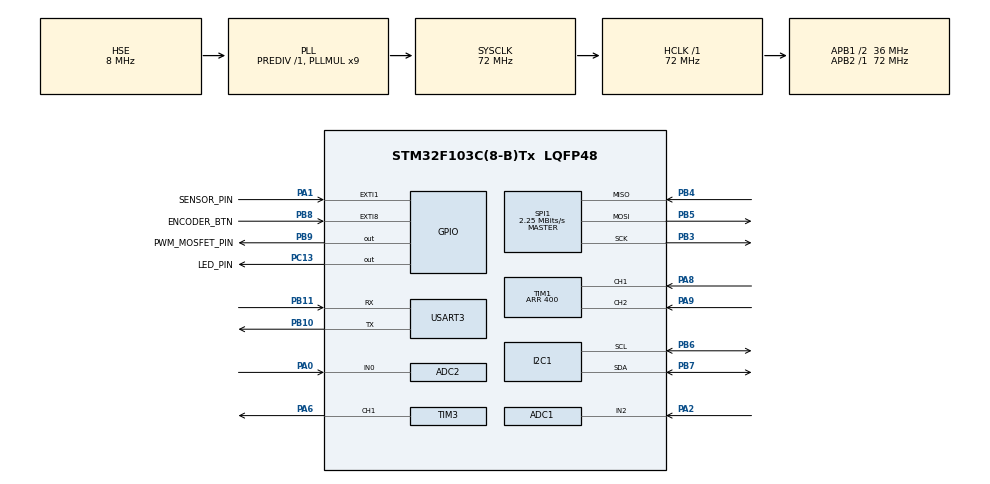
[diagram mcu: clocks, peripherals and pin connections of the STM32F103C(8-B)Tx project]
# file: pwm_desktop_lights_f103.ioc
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ADC1.Channel-1\#ChannelRegularConversion=ADC_CHANNEL_2
ADC1.ContinuousConvMode=ENABLE
ADC1.ExternalTrigConv=ADC_SOFTWARE_START
ADC1.NbrOfConversion=1
ADC1.NbrOfConversionFlag=1
ADC1.Rank-1\#ChannelRegularConversion=1
ADC1.SamplingTime-1\#ChannelRegularConversion=ADC_SAMPLETIME_13CYCLES_5
ADC1.master=1
ADC2.Channel-0\#ChannelRegularConversion=ADC_CHANNEL_0
ADC2.NbrOfConversionFlag=1
ADC2.Rank-0\#ChannelRegularConversion=1
ADC2.SamplingTime-0\#ChannelRegularConversion=ADC_SAMPLETIME_13CYCLES_5
Dma.ADC1.0.Direction=DMA_PERIPH_TO_MEMORY
Dma.ADC1.0.Instance=DMA1_Channel1
Dma.ADC1.0.MemDataAlignment=DMA_MDATAALIGN_HALFWORD
Dma.ADC1.0.MemInc=DMA_MINC_ENABLE
Dma.ADC1.0.Mode=DMA_CIRCULAR
Dma.ADC1.0.PeriphDataAlignment=DMA_PDATAALIGN_HALFWORD
Dma.ADC1.0.PeriphInc=DMA_PINC_DISABLE
Dma.ADC1.0.Priority=DMA_PRIORITY_LOW
Dma.Request0=ADC1
Dma.Request1=USART3_TX
Dma.Request2=USART3_RX
Dma.USART3_RX.2.Direction=DMA_PERIPH_TO_MEMORY
Dma.USART3_RX.2.Instance=DMA1_Channel3
Dma.USART3_RX.2.MemDataAlignment=DMA_MDATAALIGN_BYTE
Dma.USART3_RX.2.MemInc=DMA_MINC_ENABLE
Dma.USART3_RX.2.Mode=DMA_NORMAL
Dma.USART3_RX.2.PeriphDataAlignment=DMA_PDATAALIGN_BYTE
Dma.USART3_RX.2.PeriphInc=DMA_PINC_DISABLE
Dma.USART3_RX.2.Priority=DMA_PRIORITY_LOW
Dma.USART3_TX.1.Direction=DMA_MEMORY_TO_PERIPH
Dma.USART3_TX.1.Instance=DMA1_Channel2
Dma.USART3_TX.1.MemDataAlignment=DMA_MDATAALIGN_BYTE
Dma.USART3_TX.1.MemInc=DMA_MINC_ENABLE
Dma.USART3_TX.1.Mode=DMA_NORMAL
Dma.USART3_TX.1.PeriphDataAlignment=DMA_PDATAALIGN_BYTE
Dma.USART3_TX.1.PeriphInc=DMA_PINC_DISABLE
Dma.USART3_TX.1.Priority=DMA_PRIORITY_LOW
Mcu.Family=STM32F1
Mcu.Name=STM32F103C(8-B)Tx
Mcu.Package=LQFP48
NVIC.ADC1_2_IRQn=true\:0\:0\:false\:false\:true\:true\:true
NVIC.DMA1_Channel1_IRQn=true\:0\:0\:false\:false\:true\:false\:true
NVIC.DMA1_Channel2_IRQn=true\:0\:0\:false\:false\:true\:false\:true
NVIC.DMA1_Channel3_IRQn=true\:0\:0\:false\:false\:true\:false\:true
NVIC.EXTI1_IRQn=true\:0\:0\:false\:false\:true\:true\:true
NVIC.EXTI9_5_IRQn=true\:0\:0\:false\:false\:true\:true\:true
NVIC.I2C1_EV_IRQn=true\:0\:0\:false\:false\:true\:true\:true
NVIC.PriorityGroup=NVIC_PRIORITYGROUP_4
NVIC.SPI1_IRQn=true\:0\:0\:false\:false\:true\:true\:true
NVIC.TIM1_CC_IRQn=true\:0\:0\:false\:false\:true\:true\:true
NVIC.TIM1_TRG_COM_IRQn=true\:0\:0\:false\:false\:true\:true\:true
NVIC.TIM1_UP_IRQn=true\:0\:0\:false\:false\:true\:true\:true
NVIC.TIM2_IRQn=true\:0\:0\:false\:false\:true\:true\:true
NVIC.TIM3_IRQn=true\:0\:0\:false\:false\:true\:true\:true
NVIC.TIM4_IRQn=true\:0\:0\:false\:false\:true\:true\:true
NVIC.USART3_IRQn=true\:0\:0\:false\:false\:true\:true\:true
PA0-WKUP.Signal=ADCx_IN0
PA1.GPIO_Label=SENSOR_PIN
PA1.GPIO_PuPd=GPIO_PULLDOWN
PA1.Signal=GPXTI1
PA13.Mode=Serial_Wire
PA13.Signal=SYS_JTMS-SWDIO
PA14.Mode=Serial_Wire
PA14.Signal=SYS_JTCK-SWCLK
PA2.Signal=ADCx_IN2
PA6.Signal=S_TIM3_CH1
PA8.GPIO_PuPd=GPIO_PULLDOWN
PA8.Signal=S_TIM1_CH1
PA9.GPIO_PuPd=GPIO_PULLDOWN
PA9.Signal=S_TIM1_CH2
PB10.Mode=Asynchronous
PB10.Signal=USART3_TX
PB11.Mode=Asynchronous
PB11.Signal=USART3_RX
PB3.Mode=Full_Duplex_Master
PB3.Signal=SPI1_SCK
PB4.Mode=Full_Duplex_Master
PB4.Signal=SPI1_MISO
PB5.Mode=Full_Duplex_Master
PB5.Signal=SPI1_MOSI
PB6.Mode=I2C
PB6.Signal=I2C1_SCL
PB7.Mode=I2C
PB7.Signal=I2C1_SDA
PB8.GPIO_Label=ENCODER_BTN
PB8.GPIO_ModeDefaultEXTI=GPIO_MODE_IT_RISING_FALLING
PB8.GPIO_PuPd=GPIO_PULLUP
PB8.Signal=GPXTI8
PB9.GPIO_Label=PWM_MOSFET_PIN
PB9.GPIO_PuPd=GPIO_PULLDOWN
PB9.Signal=GPIO_Output
PC13-TAMPER-RTC.GPIO_Label=LED_PIN
PC13-TAMPER-RTC.GPIO_PuPd=GPIO_PULLDOWN
PC13-TAMPER-RTC.Signal=GPIO_Output
PC14-OSC32_IN.Mode=LSE-External-Oscillator
PC14-OSC32_IN.Signal=RCC_OSC32_IN
PC15-OSC32_OUT.Mode=LSE-External-Oscillator
PC15-OSC32_OUT.Signal=RCC_OSC32_OUT
PD0-OSC_IN.Mode=HSE-External-Oscillator
PD0-OSC_IN.Signal=RCC_OSC_IN
PD1-OSC_OUT.Mode=HSE-External-Oscillator
PD1-OSC_OUT.Signal=RCC_OSC_OUT
ProjectManager.HeapSize=0x200
ProjectManager.StackSize=0x400
ProjectManager.TargetToolchain=MDK-ARM V5.27
RCC.ADCPresc=RCC_ADCPCLK2_DIV6
RCC.AHBFreq_Value=72000000
RCC.APB1CLKDivider=RCC_HCLK_DIV2
RCC.APB1Freq_Value=36000000
RCC.APB1TimFreq_Value=72000000
RCC.APB2Freq_Value=72000000
RCC.APB2TimFreq_Value=72000000
RCC.HCLKFreq_Value=72000000
RCC.PLLMUL=RCC_PLL_MUL9
RCC.PLLSourceVirtual=RCC_PLLSOURCE_HSE
RCC.SYSCLKFreq_VALUE=72000000
RCC.SYSCLKSource=RCC_SYSCLKSOURCE_PLLCLK
RCC.USBFreq_Value=72000000
SH.ADCx_IN0.0=ADC2_IN0,IN0
SH.ADCx_IN2.0=ADC1_IN2,IN2
SH.S_TIM1_CH1.0=TIM1_CH1,Encoder_Interface
SH.S_TIM1_CH2.0=TIM1_CH2,Encoder_Interface
SH.S_TIM3_CH1.0=TIM3_CH1,PWM Generation1 CH1
SPI1.BaudRatePrescaler=SPI_BAUDRATEPRESCALER_32
SPI1.CalculateBaudRate=2.25 MBits/s
SPI1.Direction=SPI_DIRECTION_2LINES
SPI1.Mode=SPI_MODE_MASTER
SPI1.VirtualType=VM_MASTER
TIM1.CounterMode=TIM_COUNTERMODE_CENTERALIGNED3
TIM1.EncoderMode=TIM_ENCODERMODE_TI12
TIM1.IC1Filter=2
TIM1.IC2Filter=2
TIM1.Period=400
TIM2.Channel-Output\ Compare2\ No\ Output=TIM_CHANNEL_2
TIM2.OCMode_2=TIM_OCMODE_TOGGLE
TIM2.Period=49
TIM2.Prescaler=72
TIM2.TIM_MasterOutputTrigger=TIM_TRGO_RESET
TIM3.Channel-PWM\ Generation1\ CH1=TIM_CHANNEL_1
TIM3.Period=99
TIM3.Prescaler=72 * 5
TIM4.Channel-Output\ Compare1\ No\ Output=TIM_CHANNEL_1
TIM4.ClockDivision=TIM_CLOCKDIVISION_DIV1
TIM4.OCMode_1=TIM_OCMODE_TOGGLE
TIM4.Period=499
TIM4.Prescaler=7200 * 2
USART3.VirtualMode=VM_ASYNC
VP_TIM2_VS_no_output2.Mode=Output Compare2 No Output
VP_TIM4_VS_no_output1.Mode=Output Compare1 No Output
board=custom

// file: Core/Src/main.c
/* USER CODE BEGIN Header */
/**
  ******************************************************************************
  * @file           : main.c
  * @brief          : Main program body
  ******************************************************************************
  * @attention
  *
  * <h2><center>&copy; Copyright (c) 2019 STMicroelectronics.
  * All rights reserved.</center></h2>
  *
  * This software component is licensed by ST under BSD 3-Clause license,
  * the "License"; You may not use this file except in compliance with the
  * License. You may obtain a copy of the License at:
  *                        opensource.org/licenses/BSD-3-Clause
  *
  ******************************************************************************
  */
/* USER CODE END Header */

#include "main.h"

/* USER CODE BEGIN Includes */
#include "application.h"

/* USER CODE END Includes */

ADC_HandleTypeDef hadc1;
ADC_HandleTypeDef hadc2;
DMA_HandleTypeDef hdma_adc1;

I2C_HandleTypeDef hi2c1;

SPI_HandleTypeDef hspi1;

TIM_HandleTypeDef htim1;
TIM_HandleTypeDef htim2;
TIM_HandleTypeDef htim3;
TIM_HandleTypeDef htim4;

UART_HandleTypeDef huart3;
DMA_HandleTypeDef hdma_usart3_tx;
DMA_HandleTypeDef hdma_usart3_rx;

/* USER CODE BEGIN PV */
extern pwm_ctx_t        g_pwm_ctx;
extern error_ctx_t      g_error_ctx;
extern encoder_ctx_t    g_encoder_ctx;
extern adc_ctx_t        g_adc_ctx;

/* USER CODE END PV */

void SystemClock_Config(void);
static void MX_GPIO_Init(void);
static void MX_TIM1_Init(void);
static void MX_TIM3_Init(void);
static void MX_TIM4_Init(void);
static void MX_ADC1_Init(void);
static void MX_TIM2_Init(void);
static void MX_DMA_Init(void);
static void MX_ADC2_Init(void);
static void MX_I2C1_Init(void);
static void MX_SPI1_Init(void);
static void MX_USART3_UART_Init(void);

int main(void)
{

  /* MCU Configuration--------------------------------------------------------*/

  /* Reset of all peripherals, Initializes the Flash interface and the Systick. */
  HAL_Init();

  /* Configure the system clock */
  SystemClock_Config();

  /* Initialize all configured peripherals */
  MX_GPIO_Init();
  MX_TIM1_Init();
  MX_TIM3_Init();
  MX_TIM4_Init();
  MX_ADC1_Init();
  MX_TIM2_Init();
  MX_DMA_Init();
  MX_ADC2_Init();
  MX_I2C1_Init();
  MX_SPI1_Init();
  MX_USART3_UART_Init();
  /* USER CODE BEGIN 2 */

  error_initialize(&htim4, GPIOC, GPIO_PIN_13);
  error_start();

  pwm_initialize(&htim3);
  pwm_start();

  adc_initialize(&hadc1, &htim2);
  //adc_start();

  encoder_initialize(&htim1, ENCODER_BTN_GPIO_Port, ENCODER_BTN_Pin);
  encoder_start();

  /* USER CODE END 2 */

  /* Infinite loop */
  /* USER CODE BEGIN WHILE */
  while (1)
  {
      //__test_adc_react();
      pwm_update_target();
    /* USER CODE END WHILE */

  }
}

void SystemClock_Config(void)
{
  RCC_OscInitTypeDef RCC_OscInitStruct = {0};
  RCC_ClkInitTypeDef RCC_ClkInitStruct = {0};
  RCC_PeriphCLKInitTypeDef PeriphClkInit = {0};

  /** Initializes the CPU, AHB and APB busses clocks
  */
  RCC_OscInitStruct.OscillatorType = RCC_OSCILLATORTYPE_HSE;
  RCC_OscInitStruct.HSEState = RCC_HSE_ON;
  RCC_OscInitStruct.HSEPredivValue = RCC_HSE_PREDIV_DIV1;
  RCC_OscInitStruct.HSIState = RCC_HSI_ON;
  RCC_OscInitStruct.PLL.PLLState = RCC_PLL_ON;
  RCC_OscInitStruct.PLL.PLLSource = RCC_PLLSOURCE_HSE;
  RCC_OscInitStruct.PLL.PLLMUL = RCC_PLL_MUL9;
  if (HAL_RCC_OscConfig(&RCC_OscInitStruct) != HAL_OK)
  {
    Error_Handler();
  }
  /** Initializes the CPU, AHB and APB busses clocks
  */
  RCC_ClkInitStruct.ClockType = RCC_CLOCKTYPE_HCLK|RCC_CLOCKTYPE_SYSCLK
                              |RCC_CLOCKTYPE_PCLK1|RCC_CLOCKTYPE_PCLK2;
  RCC_ClkInitStruct.SYSCLKSource = RCC_SYSCLKSOURCE_PLLCLK;
  RCC_ClkInitStruct.AHBCLKDivider = RCC_SYSCLK_DIV1;
  RCC_ClkInitStruct.APB1CLKDivider = RCC_HCLK_DIV2;
  RCC_ClkInitStruct.APB2CLKDivider = RCC_HCLK_DIV1;

  if (HAL_RCC_ClockConfig(&RCC_ClkInitStruct, FLASH_LATENCY_2) != HAL_OK)
  {
    Error_Handler();
  }
  PeriphClkInit.PeriphClockSelection = RCC_PERIPHCLK_ADC;
  PeriphClkInit.AdcClockSelection = RCC_ADCPCLK2_DIV6;
  if (HAL_RCCEx_PeriphCLKConfig(&PeriphClkInit) != HAL_OK)
  {
    Error_Handler();
  }
}

static void MX_ADC1_Init(void)
{

  ADC_ChannelConfTypeDef sConfig = {0};

  /** Common config
  */
  hadc1.Instance = ADC1;
  hadc1.Init.ScanConvMode = ADC_SCAN_DISABLE;
  hadc1.Init.ContinuousConvMode = ENABLE;
  hadc1.Init.DiscontinuousConvMode = DISABLE;
  hadc1.Init.ExternalTrigConv = ADC_SOFTWARE_START;
  hadc1.Init.DataAlign = ADC_DATAALIGN_RIGHT;
  hadc1.Init.NbrOfConversion = 1;
  if (HAL_ADC_Init(&hadc1) != HAL_OK)
  {
    Error_Handler();
  }
  /** Configure Regular Channel
  */
  sConfig.Channel = ADC_CHANNEL_2;
  sConfig.Rank = ADC_REGULAR_RANK_1;
  sConfig.SamplingTime = ADC_SAMPLETIME_13CYCLES_5;
  if (HAL_ADC_ConfigChannel(&hadc1, &sConfig) != HAL_OK)
  {
    Error_Handler();
  }

}

static void MX_ADC2_Init(void)
{

  ADC_ChannelConfTypeDef sConfig = {0};

  /** Common config
  */
  hadc2.Instance = ADC2;
  hadc2.Init.ScanConvMode = ADC_SCAN_DISABLE;
  hadc2.Init.ContinuousConvMode = DISABLE;
  hadc2.Init.DiscontinuousConvMode = DISABLE;
  hadc2.Init.ExternalTrigConv = ADC_SOFTWARE_START;
  hadc2.Init.DataAlign = ADC_DATAALIGN_RIGHT;
  hadc2.Init.NbrOfConversion = 1;
  if (HAL_ADC_Init(&hadc2) != HAL_OK)
  {
    Error_Handler();
  }
  /** Configure Regular Channel
  */
  sConfig.Channel = ADC_CHANNEL_0;
  sConfig.Rank = ADC_REGULAR_RANK_1;
  sConfig.SamplingTime = ADC_SAMPLETIME_13CYCLES_5;
  if (HAL_ADC_ConfigChannel(&hadc2, &sConfig) != HAL_OK)
  {
    Error_Handler();
  }

}

static void MX_I2C1_Init(void)
{

  hi2c1.Instance = I2C1;
  hi2c1.Init.ClockSpeed = 100000;
  hi2c1.Init.DutyCycle = I2C_DUTYCYCLE_2;
  hi2c1.Init.OwnAddress1 = 0;
  hi2c1.Init.AddressingMode = I2C_ADDRESSINGMODE_7BIT;
  hi2c1.Init.DualAddressMode = I2C_DUALADDRESS_DISABLE;
  hi2c1.Init.OwnAddress2 = 0;
  hi2c1.Init.GeneralCallMode = I2C_GENERALCALL_DISABLE;
  hi2c1.Init.NoStretchMode = I2C_NOSTRETCH_DISABLE;
  if (HAL_I2C_Init(&hi2c1) != HAL_OK)
  {
    Error_Handler();
  }

}

static void MX_SPI1_Init(void)
{

  /* SPI1 parameter configuration*/
  hspi1.Instance = SPI1;
  hspi1.Init.Mode = SPI_MODE_MASTER;
  hspi1.Init.Direction = SPI_DIRECTION_2LINES;
  hspi1.Init.DataSize = SPI_DATASIZE_8BIT;
  hspi1.Init.CLKPolarity = SPI_POLARITY_LOW;
  hspi1.Init.CLKPhase = SPI_PHASE_1EDGE;
  hspi1.Init.NSS = SPI_NSS_SOFT;
  hspi1.Init.BaudRatePrescaler = SPI_BAUDRATEPRESCALER_32;
  hspi1.Init.FirstBit = SPI_FIRSTBIT_MSB;
  hspi1.Init.TIMode = SPI_TIMODE_DISABLE;
  hspi1.Init.CRCCalculation = SPI_CRCCALCULATION_DISABLE;
  hspi1.Init.CRCPolynomial = 10;
  if (HAL_SPI_Init(&hspi1) != HAL_OK)
  {
    Error_Handler();
  }

}

static void MX_TIM1_Init(void)
{

  TIM_Encoder_InitTypeDef sConfig = {0};
  TIM_MasterConfigTypeDef sMasterConfig = {0};

  htim1.Instance = TIM1;
  htim1.Init.Prescaler = 0;
  htim1.Init.CounterMode = TIM_COUNTERMODE_CENTERALIGNED3;
  htim1.Init.Period = 400;
  htim1.Init.ClockDivision = TIM_CLOCKDIVISION_DIV1;
  htim1.Init.RepetitionCounter = 0;
  htim1.Init.AutoReloadPreload = TIM_AUTORELOAD_PRELOAD_DISABLE;
  sConfig.EncoderMode = TIM_ENCODERMODE_TI12;
  sConfig.IC1Polarity = TIM_ICPOLARITY_RISING;
  sConfig.IC1Selection = TIM_ICSELECTION_DIRECTTI;
  sConfig.IC1Prescaler = TIM_ICPSC_DIV1;
  sConfig.IC1Filter = 2;
  sConfig.IC2Polarity = TIM_ICPOLARITY_RISING;
  sConfig.IC2Selection = TIM_ICSELECTION_DIRECTTI;
  sConfig.IC2Prescaler = TIM_ICPSC_DIV1;
  sConfig.IC2Filter = 2;
  if (HAL_TIM_Encoder_Init(&htim1, &sConfig) != HAL_OK)
  {
    Error_Handler();
  }
  sMasterConfig.MasterOutputTrigger = TIM_TRGO_RESET;
  sMasterConfig.MasterSlaveMode = TIM_MASTERSLAVEMODE_DISABLE;
  if (HAL_TIMEx_MasterConfigSynchronization(&htim1, &sMasterConfig) != HAL_OK)
  {
    Error_Handler();
  }

}

static void MX_TIM2_Init(void)
{

  TIM_MasterConfigTypeDef sMasterConfig = {0};
  TIM_OC_InitTypeDef sConfigOC = {0};

  htim2.Instance = TIM2;
  htim2.Init.Prescaler = 72;
  htim2.Init.CounterMode = TIM_COUNTERMODE_UP;
  htim2.Init.Period = 49;
  htim2.Init.ClockDivision = TIM_CLOCKDIVISION_DIV1;
  htim2.Init.AutoReloadPreload = TIM_AUTORELOAD_PRELOAD_DISABLE;
  if (HAL_TIM_OC_Init(&htim2) != HAL_OK)
  {
    Error_Handler();
  }
  sMasterConfig.MasterOutputTrigger = TIM_TRGO_RESET;
  sMasterConfig.MasterSlaveMode = TIM_MASTERSLAVEMODE_DISABLE;
  if (HAL_TIMEx_MasterConfigSynchronization(&htim2, &sMasterConfig) != HAL_OK)
  {
    Error_Handler();
  }
  sConfigOC.OCMode = TIM_OCMODE_TOGGLE;
  sConfigOC.Pulse = 0;
  sConfigOC.OCPolarity = TIM_OCPOLARITY_HIGH;
  sConfigOC.OCFastMode = TIM_OCFAST_DISABLE;
  if (HAL_TIM_OC_ConfigChannel(&htim2, &sConfigOC, TIM_CHANNEL_2) != HAL_OK)
  {
    Error_Handler();
  }

}

static void MX_TIM3_Init(void)
{

  TIM_MasterConfigTypeDef sMasterConfig = {0};
  TIM_OC_InitTypeDef sConfigOC = {0};

  htim3.Instance = TIM3;
  htim3.Init.Prescaler = 72 * 5;
  htim3.Init.CounterMode = TIM_COUNTERMODE_UP;
  htim3.Init.Period = 99;
  htim3.Init.ClockDivision = TIM_CLOCKDIVISION_DIV1;
  htim3.Init.AutoReloadPreload = TIM_AUTORELOAD_PRELOAD_DISABLE;
  if (HAL_TIM_PWM_Init(&htim3) != HAL_OK)
  {
    Error_Handler();
  }
  sMasterConfig.MasterOutputTrigger = TIM_TRGO_RESET;
  sMasterConfig.MasterSlaveMode = TIM_MASTERSLAVEMODE_DISABLE;
  if (HAL_TIMEx_MasterConfigSynchronization(&htim3, &sMasterConfig) != HAL_OK)
  {
    Error_Handler();
  }
  sConfigOC.OCMode = TIM_OCMODE_PWM1;
  sConfigOC.Pulse = 0;
  sConfigOC.OCPolarity = TIM_OCPOLARITY_HIGH;
  sConfigOC.OCFastMode = TIM_OCFAST_DISABLE;
  if (HAL_TIM_PWM_ConfigChannel(&htim3, &sConfigOC, TIM_CHANNEL_1) != HAL_OK)
  {
    Error_Handler();
  }
  HAL_TIM_MspPostInit(&htim3);

}

static void MX_TIM4_Init(void)
{

  TIM_MasterConfigTypeDef sMasterConfig = {0};
  TIM_OC_InitTypeDef sConfigOC = {0};

  htim4.Instance = TIM4;
  htim4.Init.Prescaler = 7200 * 2;
  htim4.Init.CounterMode = TIM_COUNTERMODE_UP;
  htim4.Init.Period = 499;
  htim4.Init.ClockDivision = TIM_CLOCKDIVISION_DIV1;
  htim4.Init.AutoReloadPreload = TIM_AUTORELOAD_PRELOAD_DISABLE;
  if (HAL_TIM_OC_Init(&htim4) != HAL_OK)
  {
    Error_Handler();
  }
  sMasterConfig.MasterOutputTrigger = TIM_TRGO_RESET;
  sMasterConfig.MasterSlaveMode = TIM_MASTERSLAVEMODE_DISABLE;
  if (HAL_TIMEx_MasterConfigSynchronization(&htim4, &sMasterConfig) != HAL_OK)
  {
    Error_Handler();
  }
  sConfigOC.OCMode = TIM_OCMODE_TOGGLE;
  sConfigOC.Pulse = 0;
  sConfigOC.OCPolarity = TIM_OCPOLARITY_HIGH;
  sConfigOC.OCFastMode = TIM_OCFAST_DISABLE;
  if (HAL_TIM_OC_ConfigChannel(&htim4, &sConfigOC, TIM_CHANNEL_1) != HAL_OK)
  {
    Error_Handler();
  }

}

static void MX_USART3_UART_Init(void)
{

  huart3.Instance = USART3;
  huart3.Init.BaudRate = 115200;
  huart3.Init.WordLength = UART_WORDLENGTH_8B;
  huart3.Init.StopBits = UART_STOPBITS_1;
  huart3.Init.Parity = UART_PARITY_NONE;
  huart3.Init.Mode = UART_MODE_TX_RX;
  huart3.Init.HwFlowCtl = UART_HWCONTROL_NONE;
  huart3.Init.OverSampling = UART_OVERSAMPLING_16;
  if (HAL_UART_Init(&huart3) != HAL_OK)
  {
    Error_Handler();
  }

}

static void MX_DMA_Init(void)
{

  /* DMA controller clock enable */
  __HAL_RCC_DMA1_CLK_ENABLE();

  /* DMA interrupt init */
  /* DMA1_Channel1_IRQn interrupt configuration */
  HAL_NVIC_SetPriority(DMA1_Channel1_IRQn, 0, 0);
  HAL_NVIC_EnableIRQ(DMA1_Channel1_IRQn);
  /* DMA1_Channel2_IRQn interrupt configuration */
  HAL_NVIC_SetPriority(DMA1_Channel2_IRQn, 0, 0);
  HAL_NVIC_EnableIRQ(DMA1_Channel2_IRQn);
  /* DMA1_Channel3_IRQn interrupt configuration */
  HAL_NVIC_SetPriority(DMA1_Channel3_IRQn, 0, 0);
  HAL_NVIC_EnableIRQ(DMA1_Channel3_IRQn);

}

static void MX_GPIO_Init(void)
{
  GPIO_InitTypeDef GPIO_InitStruct = {0};

  /* GPIO Ports Clock Enable */
  __HAL_RCC_GPIOC_CLK_ENABLE();
  __HAL_RCC_GPIOD_CLK_ENABLE();
  __HAL_RCC_GPIOA_CLK_ENABLE();
  __HAL_RCC_GPIOB_CLK_ENABLE();

  /*Configure GPIO pin Output Level */
  HAL_GPIO_WritePin(LED_PIN_GPIO_Port, LED_PIN_Pin, GPIO_PIN_RESET);

  /*Configure GPIO pin Output Level */
  HAL_GPIO_WritePin(PWM_MOSFET_PIN_GPIO_Port, PWM_MOSFET_PIN_Pin, GPIO_PIN_RESET);

  /*Configure GPIO pin : LED_PIN_Pin */
  GPIO_InitStruct.Pin = LED_PIN_Pin;
  GPIO_InitStruct.Mode = GPIO_MODE_OUTPUT_PP;
  GPIO_InitStruct.Pull = GPIO_PULLDOWN;
  GPIO_InitStruct.Speed = GPIO_SPEED_FREQ_LOW;
  HAL_GPIO_Init(LED_PIN_GPIO_Port, &GPIO_InitStruct);

  /*Configure GPIO pin : SENSOR_PIN_Pin */
  GPIO_InitStruct.Pin = SENSOR_PIN_Pin;
  GPIO_InitStruct.Mode = GPIO_MODE_IT_RISING;
  GPIO_InitStruct.Pull = GPIO_PULLDOWN;
  HAL_GPIO_Init(SENSOR_PIN_GPIO_Port, &GPIO_InitStruct);

  /*Configure GPIO pin : ENCODER_BTN_Pin */
  GPIO_InitStruct.Pin = ENCODER_BTN_Pin;
  GPIO_InitStruct.Mode = GPIO_MODE_IT_RISING_FALLING;
  GPIO_InitStruct.Pull = GPIO_PULLUP;
  HAL_GPIO_Init(ENCODER_BTN_GPIO_Port, &GPIO_InitStruct);

  /*Configure GPIO pin : PWM_MOSFET_PIN_Pin */
  GPIO_InitStruct.Pin = PWM_MOSFET_PIN_Pin;
  GPIO_InitStruct.Mode = GPIO_MODE_OUTPUT_PP;
  GPIO_InitStruct.Pull = GPIO_PULLDOWN;
  GPIO_InitStruct.Speed = GPIO_SPEED_FREQ_LOW;
  HAL_GPIO_Init(PWM_MOSFET_PIN_GPIO_Port, &GPIO_InitStruct);

  /* EXTI interrupt init*/
  HAL_NVIC_SetPriority(EXTI1_IRQn, 0, 0);
  HAL_NVIC_EnableIRQ(EXTI1_IRQn);

  HAL_NVIC_SetPriority(EXTI9_5_IRQn, 0, 0);
  HAL_NVIC_EnableIRQ(EXTI9_5_IRQn);

}

void Error_Handler(void)
{
}

/************************ (C) COPYRIGHT STMicroelectronics *****END OF FILE****/
